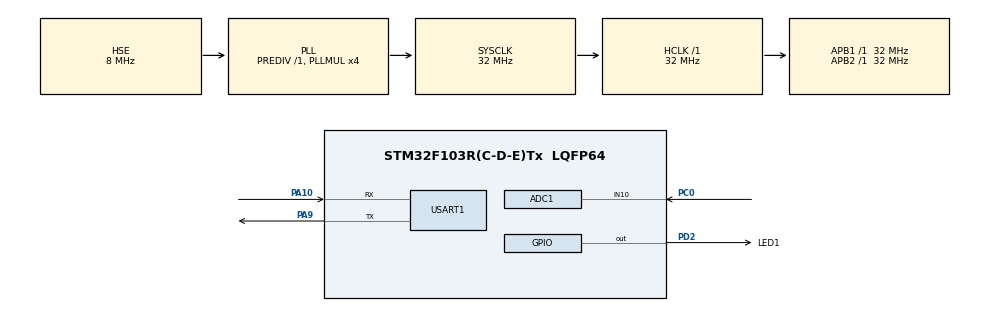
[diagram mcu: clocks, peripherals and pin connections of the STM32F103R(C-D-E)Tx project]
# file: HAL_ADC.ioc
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ADC1.Channel-2\#ChannelRegularConversion=ADC_CHANNEL_10
ADC1.NbrOfConversionFlag=1
ADC1.Rank-2\#ChannelRegularConversion=1
ADC1.SamplingTime-2\#ChannelRegularConversion=ADC_SAMPLETIME_1CYCLE_5
ADC1.master=1
Mcu.Family=STM32F1
Mcu.Name=STM32F103R(C-D-E)Tx
Mcu.Package=LQFP64
NVIC.ADC1_2_IRQn=true\:0\:0\:false\:false\:true\:true\:true
NVIC.PriorityGroup=NVIC_PRIORITYGROUP_4
NVIC.USART1_IRQn=true\:0\:0\:false\:false\:true\:true\:true
PA10.Mode=Asynchronous
PA10.Signal=USART1_RX
PA13.Mode=Serial_Wire
PA13.Signal=SYS_JTMS-SWDIO
PA14.Mode=Serial_Wire
PA14.Signal=SYS_JTCK-SWCLK
PA9.Mode=Asynchronous
PA9.Signal=USART1_TX
PC0.Signal=ADCx_IN10
PD0-OSC_IN.Mode=HSE-External-Oscillator
PD0-OSC_IN.Signal=RCC_OSC_IN
PD1-OSC_OUT.Mode=HSE-External-Oscillator
PD1-OSC_OUT.Signal=RCC_OSC_OUT
PD2.GPIO_Label=LED1
PD2.GPIO_Speed=GPIO_SPEED_FREQ_MEDIUM
PD2.PinState=GPIO_PIN_SET
PD2.Signal=GPIO_Output
ProjectManager.HeapSize=0x200
ProjectManager.StackSize=0x400
ProjectManager.TargetToolchain=Other Toolchains (GPDSC)
RCC.ADCPresc=RCC_ADCPCLK2_DIV4
RCC.AHBFreq_Value=32000000
RCC.APB1Freq_Value=32000000
RCC.APB1TimFreq_Value=32000000
RCC.APB2Freq_Value=32000000
RCC.APB2TimFreq_Value=32000000
RCC.HCLKFreq_Value=32000000
RCC.PLLMUL=RCC_PLL_MUL4
RCC.PLLSourceVirtual=RCC_PLLSOURCE_HSE
RCC.SYSCLKFreq_VALUE=32000000
RCC.SYSCLKSource=RCC_SYSCLKSOURCE_PLLCLK
RCC.USBFreq_Value=32000000
SH.ADCx_IN10.0=ADC1_IN10,IN10
USART1.VirtualMode=VM_ASYNC
board=custom

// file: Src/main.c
/* USER CODE BEGIN Header */
/**
  ******************************************************************************
  * @file           : main.c
  * @brief          : Main program body
  ******************************************************************************
  * @attention
  *
  * <h2><center>&copy; Copyright (c) 2020 STMicroelectronics.
  * All rights reserved.</center></h2>
  *
  * This software component is licensed by ST under BSD 3-Clause license,
  * the "License"; You may not use this file except in compliance with the
  * License. You may obtain a copy of the License at:
  *                        opensource.org/licenses/BSD-3-Clause
  *
  ******************************************************************************
  */
/* USER CODE END Header */

#include "main.h"
#include "adc.h"
#include "usart.h"
#include "gpio.h"
#include "stdio.h"

void SystemClock_Config(void);

/* USER CODE BEGIN 0 */
#define LED1_ON() HAL_GPIO_WritePin(GPIOD,GPIO_PIN_2,GPIO_PIN_RESET)
#define LED1_OFF() HAL_GPIO_WritePin(GPIOD,GPIO_PIN_2,GPIO_PIN_SET)

uint16_t ADC_value = 0, ADC_Volt = 0;
uint8_t str_buff[64];

void UR1_Send()
{
	sprintf((char*)str_buff, "采样值:%d, 电压值:%d.%d%dV\r\n", ADC_value, ADC_Volt / 1000, (ADC_Volt % 1000) / 100, (ADC_Volt % 100) / 10);
	HAL_UART_Transmit(&huart1, str_buff, sizeof(str_buff), 10000);
}

//void ADC1_Get_Value()
//{
//	HAL_ADC_Start(&hadc1);
//	LED1_ON();
//	if (HAL_ADC_PollForConversion(&hadc1, 10) == HAL_OK)
//	{
//		ADC_value = HAL_ADC_GetValue(&hadc1);
//		ADC_Volt = ADC_value * 3300 / 4096;		//mV
//	}
//	UR1_Send();
//}
/* USER CODE END 0 */

void HAL_ADC_ConvCpltCallback(ADC_HandleTypeDef*hadc)
{
	if (hadc->Instance == ADC1)
	{
		ADC_value = HAL_ADC_GetValue(&hadc1);
		ADC_Volt = ADC_value * 3300 / 4096;		//mV
		UR1_Send();
		LED1_OFF();
	}
}
int main(void)
{

  /* MCU Configuration--------------------------------------------------------*/

  /* Reset of all peripherals, Initializes the Flash interface and the Systick. */
  HAL_Init();

  /* Configure the system clock */
  SystemClock_Config();

  /* Initialize all configured peripherals */
  MX_GPIO_Init();
  MX_ADC1_Init();
  MX_USART1_UART_Init();

  /* Infinite loop */
  /* USER CODE BEGIN WHILE */
  while (1)
  {
	  LED1_ON();
	  HAL_ADC_Start_IT(&hadc1);
	  HAL_Delay(500);
    /* USER CODE END WHILE */

  }
}

void SystemClock_Config(void)
{
  RCC_OscInitTypeDef RCC_OscInitStruct = {0};
  RCC_ClkInitTypeDef RCC_ClkInitStruct = {0};
  RCC_PeriphCLKInitTypeDef PeriphClkInit = {0};

  /** Initializes the CPU, AHB and APB busses clocks
  */
  RCC_OscInitStruct.OscillatorType = RCC_OSCILLATORTYPE_HSE;
  RCC_OscInitStruct.HSEState = RCC_HSE_ON;
  RCC_OscInitStruct.HSEPredivValue = RCC_HSE_PREDIV_DIV1;
  RCC_OscInitStruct.HSIState = RCC_HSI_ON;
  RCC_OscInitStruct.PLL.PLLState = RCC_PLL_ON;
  RCC_OscInitStruct.PLL.PLLSource = RCC_PLLSOURCE_HSE;
  RCC_OscInitStruct.PLL.PLLMUL = RCC_PLL_MUL4;
  if (HAL_RCC_OscConfig(&RCC_OscInitStruct) != HAL_OK)
  {
    Error_Handler();
  }
  /** Initializes the CPU, AHB and APB busses clocks
  */
  RCC_ClkInitStruct.ClockType = RCC_CLOCKTYPE_HCLK|RCC_CLOCKTYPE_SYSCLK
                              |RCC_CLOCKTYPE_PCLK1|RCC_CLOCKTYPE_PCLK2;
  RCC_ClkInitStruct.SYSCLKSource = RCC_SYSCLKSOURCE_PLLCLK;
  RCC_ClkInitStruct.AHBCLKDivider = RCC_SYSCLK_DIV1;
  RCC_ClkInitStruct.APB1CLKDivider = RCC_HCLK_DIV1;
  RCC_ClkInitStruct.APB2CLKDivider = RCC_HCLK_DIV1;

  if (HAL_RCC_ClockConfig(&RCC_ClkInitStruct, FLASH_LATENCY_1) != HAL_OK)
  {
    Error_Handler();
  }
  PeriphClkInit.PeriphClockSelection = RCC_PERIPHCLK_ADC;
  PeriphClkInit.AdcClockSelection = RCC_ADCPCLK2_DIV4;
  if (HAL_RCCEx_PeriphCLKConfig(&PeriphClkInit) != HAL_OK)
  {
    Error_Handler();
  }
}

void Error_Handler(void)
{
}

/************************ (C) COPYRIGHT STMicroelectronics *****END OF FILE****/
